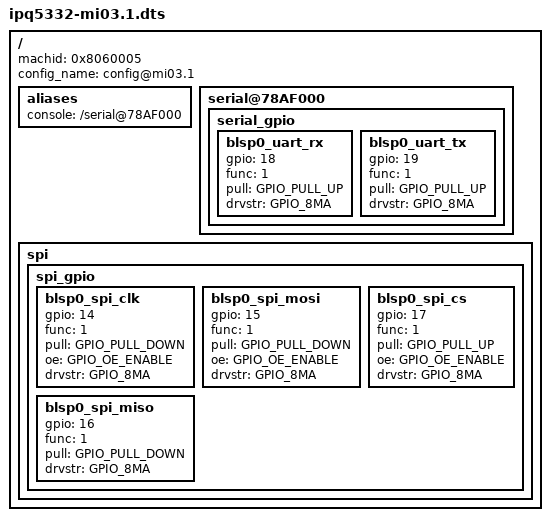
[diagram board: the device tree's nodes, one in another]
/*
 * Copyright (c) 2016-2019, The Linux Foundation. All rights reserved.
 *
 * Copyright (c) 2022 Qualcomm Innovation Center, Inc. All rights reserved.
 *
 * This program is free software; you can redistribute it and/or modify
 * it under the terms of the GNU General Public License version 2 and
 * only version 2 as published by the Free Software Foundation.
 *
 * This program is distributed in the hope that it will be useful,
 * but WITHOUT ANY WARRANTY; without even the implied warranty of
 * MERCHANTABILITY or FITNESS FOR A PARTICULAR PURPOSE.  See the
 * GNU General Public License for more details.
 */

/dts-v1/;
#include "ipq5332-soc.dtsi"
/ {
	machid = <0x8060005>;
	config_name = "config@mi03.1";

	aliases {
		console = "/serial@78AF000";
	};

	serial@78AF000 {
		status = "ok";
		serial_gpio {
			blsp0_uart_rx {
				gpio = <18>;
				func = <1>;
				pull = <GPIO_PULL_UP>;
				drvstr = <GPIO_8MA>;
			};
			blsp0_uart_tx {
				gpio = <19>;
				func = <1>;
				pull = <GPIO_PULL_UP>;
				drvstr = <GPIO_8MA>;
			};
		};
	};

	spi {
		spi_gpio {
			blsp0_spi_clk {
				gpio = <14>;
				func = <1>;
				pull = <GPIO_PULL_DOWN>;
				oe = <GPIO_OE_ENABLE>;
				drvstr = <GPIO_8MA>;
			};
			blsp0_spi_mosi {
				gpio = <15>;
				func = <1>;
				pull = <GPIO_PULL_DOWN>;
				oe = <GPIO_OE_ENABLE>;
				drvstr = <GPIO_8MA>;
			};
			blsp0_spi_miso {
				gpio = <16>;
				func = <1>;
				pull = <GPIO_PULL_DOWN>;
				drvstr = <GPIO_8MA>;
			};
			blsp0_spi_cs {
				gpio = <17>;
				func = <1>;
				pull = <GPIO_PULL_UP>;
				oe = <GPIO_OE_ENABLE>;
				drvstr = <GPIO_8MA>;
			};
		};
	};
};
